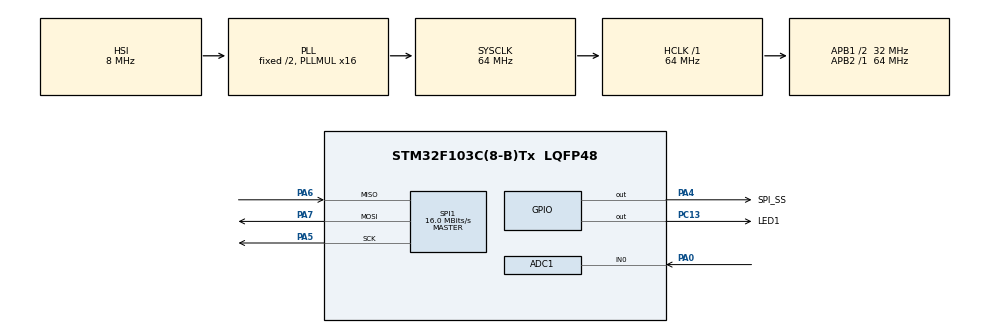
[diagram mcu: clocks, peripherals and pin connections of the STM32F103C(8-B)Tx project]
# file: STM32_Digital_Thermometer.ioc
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ADC1.Channel-0\#ChannelRegularConversion=ADC_CHANNEL_0
ADC1.NbrOfConversionFlag=1
ADC1.Rank-0\#ChannelRegularConversion=1
ADC1.SamplingTime-0\#ChannelRegularConversion=ADC_SAMPLETIME_28CYCLES_5
ADC1.master=1
Mcu.Family=STM32F1
Mcu.Name=STM32F103C(8-B)Tx
Mcu.Package=LQFP48
NVIC.PriorityGroup=NVIC_PRIORITYGROUP_4
PA0-WKUP.Signal=ADCx_IN0
PA13.Mode=Serial_Wire
PA13.Signal=SYS_JTMS-SWDIO
PA14.Mode=Serial_Wire
PA14.Signal=SYS_JTCK-SWCLK
PA4.GPIO_Label=SPI_SS
PA4.Signal=GPIO_Output
PA5.Mode=Full_Duplex_Master
PA5.Signal=SPI1_SCK
PA6.Mode=Full_Duplex_Master
PA6.Signal=SPI1_MISO
PA7.Mode=Full_Duplex_Master
PA7.Signal=SPI1_MOSI
PC13-TAMPER-RTC.GPIO_Label=LED1
PC13-TAMPER-RTC.Signal=GPIO_Output
ProjectManager.HeapSize=0x1000
ProjectManager.StackSize=0x800
ProjectManager.TargetToolchain=MDK-ARM V5.32
RCC.ADCPresc=RCC_ADCPCLK2_DIV6
RCC.AHBFreq_Value=64000000
RCC.APB1CLKDivider=RCC_HCLK_DIV2
RCC.APB1Freq_Value=32000000
RCC.APB1TimFreq_Value=64000000
RCC.APB2Freq_Value=64000000
RCC.APB2TimFreq_Value=64000000
RCC.HCLKFreq_Value=64000000
RCC.PLLMUL=RCC_PLL_MUL16
RCC.SYSCLKFreq_VALUE=64000000
RCC.SYSCLKSource=RCC_SYSCLKSOURCE_PLLCLK
RCC.USBFreq_Value=64000000
SH.ADCx_IN0.0=ADC1_IN0,IN0
SPI1.BaudRatePrescaler=SPI_BAUDRATEPRESCALER_4
SPI1.CalculateBaudRate=16.0 MBits/s
SPI1.DataSize=SPI_DATASIZE_16BIT
SPI1.Direction=SPI_DIRECTION_2LINES
SPI1.Mode=SPI_MODE_MASTER
SPI1.VirtualType=VM_MASTER
board=custom

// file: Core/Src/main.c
/* USER CODE BEGIN Header */
/**
  ******************************************************************************
  * @file           : main.c
  * @brief          : Main program body
  ******************************************************************************
  * @attention
  *
  * Copyright (c) 2025 STMicroelectronics.
  * All rights reserved.
  *
  * This software is licensed under terms that can be found in the LICENSE file
  * in the root directory of this software component.
  * If no LICENSE file comes with this software, it is provided AS-IS.
  *
  ******************************************************************************
  */
/* USER CODE END Header */
#include "main.h"

/* USER CODE BEGIN Includes */
#include "seven_segment.h"
#include "temp_adc.h"
/* USER CODE END Includes */

ADC_HandleTypeDef hadc1;

SPI_HandleTypeDef hspi1;

void SystemClock_Config(void);
static void MX_GPIO_Init(void);
static void MX_ADC1_Init(void);
static void MX_SPI1_Init(void);

int main(void)
{

  /* MCU Configuration--------------------------------------------------------*/

  /* Reset of all peripherals, Initializes the Flash interface and the Systick. */
  HAL_Init();

  /* Configure the system clock */
  SystemClock_Config();

  /* Initialize all configured peripherals */
  MX_GPIO_Init();
  MX_ADC1_Init();
  MX_SPI1_Init();
  /* USER CODE BEGIN 2 */
	SPI1_init();
	temp_adc_init();

	DisplayDigits_t display_digits; // Initialise Digital Display structure

	temp_adc_start_conversion(); // Start Temperature Converison
  /* USER CODE END 2 */

  /* Infinite loop */
  /* USER CODE BEGIN WHILE */
  while (1)
  {
		// Read Temperature when conversion is done
		if (temp_adc_is_ready()) // If conversion is complete
		{
			float temperature = temp_adc_read_celsius(); // Get Temperature Value

			Temperature_To_Digit(temperature, &display_digits); // Convert to format for 7Segment
			Update_Display(&display_digits); // Display on 7Segment

			temp_adc_start_conversion();  // Start Next conversion
		}

    /* USER CODE END WHILE */

  }
}

void SystemClock_Config(void)
{
  RCC_OscInitTypeDef RCC_OscInitStruct = {0};
  RCC_ClkInitTypeDef RCC_ClkInitStruct = {0};
  RCC_PeriphCLKInitTypeDef PeriphClkInit = {0};

  /** Initializes the RCC Oscillators according to the specified parameters
  * in the RCC_OscInitTypeDef structure.
  */
  RCC_OscInitStruct.OscillatorType = RCC_OSCILLATORTYPE_HSI;
  RCC_OscInitStruct.HSIState = RCC_HSI_ON;
  RCC_OscInitStruct.HSICalibrationValue = RCC_HSICALIBRATION_DEFAULT;
  RCC_OscInitStruct.PLL.PLLState = RCC_PLL_ON;
  RCC_OscInitStruct.PLL.PLLSource = RCC_PLLSOURCE_HSI_DIV2;
  RCC_OscInitStruct.PLL.PLLMUL = RCC_PLL_MUL16;
  if (HAL_RCC_OscConfig(&RCC_OscInitStruct) != HAL_OK)
  {
    Error_Handler();
  }

  /** Initializes the CPU, AHB and APB buses clocks
  */
  RCC_ClkInitStruct.ClockType = RCC_CLOCKTYPE_HCLK|RCC_CLOCKTYPE_SYSCLK
                              |RCC_CLOCKTYPE_PCLK1|RCC_CLOCKTYPE_PCLK2;
  RCC_ClkInitStruct.SYSCLKSource = RCC_SYSCLKSOURCE_PLLCLK;
  RCC_ClkInitStruct.AHBCLKDivider = RCC_SYSCLK_DIV1;
  RCC_ClkInitStruct.APB1CLKDivider = RCC_HCLK_DIV2;
  RCC_ClkInitStruct.APB2CLKDivider = RCC_HCLK_DIV1;

  if (HAL_RCC_ClockConfig(&RCC_ClkInitStruct, FLASH_LATENCY_2) != HAL_OK)
  {
    Error_Handler();
  }
  PeriphClkInit.PeriphClockSelection = RCC_PERIPHCLK_ADC;
  PeriphClkInit.AdcClockSelection = RCC_ADCPCLK2_DIV6;
  if (HAL_RCCEx_PeriphCLKConfig(&PeriphClkInit) != HAL_OK)
  {
    Error_Handler();
  }
}

static void MX_ADC1_Init(void)
{

  ADC_ChannelConfTypeDef sConfig = {0};

  /** Common config
  */
  hadc1.Instance = ADC1;
  hadc1.Init.ScanConvMode = ADC_SCAN_DISABLE;
  hadc1.Init.ContinuousConvMode = DISABLE;
  hadc1.Init.DiscontinuousConvMode = DISABLE;
  hadc1.Init.ExternalTrigConv = ADC_SOFTWARE_START;
  hadc1.Init.DataAlign = ADC_DATAALIGN_RIGHT;
  hadc1.Init.NbrOfConversion = 1;
  if (HAL_ADC_Init(&hadc1) != HAL_OK)
  {
    Error_Handler();
  }

  /** Configure Regular Channel
  */
  sConfig.Channel = ADC_CHANNEL_0;
  sConfig.Rank = ADC_REGULAR_RANK_1;
  sConfig.SamplingTime = ADC_SAMPLETIME_28CYCLES_5;
  if (HAL_ADC_ConfigChannel(&hadc1, &sConfig) != HAL_OK)
  {
    Error_Handler();
  }

}

static void MX_SPI1_Init(void)
{

  /* SPI1 parameter configuration*/
  hspi1.Instance = SPI1;
  hspi1.Init.Mode = SPI_MODE_MASTER;
  hspi1.Init.Direction = SPI_DIRECTION_2LINES;
  hspi1.Init.DataSize = SPI_DATASIZE_16BIT;
  hspi1.Init.CLKPolarity = SPI_POLARITY_LOW;
  hspi1.Init.CLKPhase = SPI_PHASE_1EDGE;
  hspi1.Init.NSS = SPI_NSS_SOFT;
  hspi1.Init.BaudRatePrescaler = SPI_BAUDRATEPRESCALER_4;
  hspi1.Init.FirstBit = SPI_FIRSTBIT_MSB;
  hspi1.Init.TIMode = SPI_TIMODE_DISABLE;
  hspi1.Init.CRCCalculation = SPI_CRCCALCULATION_DISABLE;
  hspi1.Init.CRCPolynomial = 10;
  if (HAL_SPI_Init(&hspi1) != HAL_OK)
  {
    Error_Handler();
  }

}

static void MX_GPIO_Init(void)
{
  GPIO_InitTypeDef GPIO_InitStruct = {0};

  /* GPIO Ports Clock Enable */
  __HAL_RCC_GPIOC_CLK_ENABLE();
  __HAL_RCC_GPIOA_CLK_ENABLE();

  /*Configure GPIO pin Output Level */
  HAL_GPIO_WritePin(LED1_GPIO_Port, LED1_Pin, GPIO_PIN_RESET);

  /*Configure GPIO pin Output Level */
  HAL_GPIO_WritePin(SPI_SS_GPIO_Port, SPI_SS_Pin, GPIO_PIN_RESET);

  /*Configure GPIO pin : LED1_Pin */
  GPIO_InitStruct.Pin = LED1_Pin;
  GPIO_InitStruct.Mode = GPIO_MODE_OUTPUT_PP;
  GPIO_InitStruct.Pull = GPIO_NOPULL;
  GPIO_InitStruct.Speed = GPIO_SPEED_FREQ_LOW;
  HAL_GPIO_Init(LED1_GPIO_Port, &GPIO_InitStruct);

  /*Configure GPIO pin : SPI_SS_Pin */
  GPIO_InitStruct.Pin = SPI_SS_Pin;
  GPIO_InitStruct.Mode = GPIO_MODE_OUTPUT_PP;
  GPIO_InitStruct.Pull = GPIO_NOPULL;
  GPIO_InitStruct.Speed = GPIO_SPEED_FREQ_LOW;
  HAL_GPIO_Init(SPI_SS_GPIO_Port, &GPIO_InitStruct);

}

void Error_Handler(void)
{
  __disable_irq();
  while (1)
  {
  }
}
